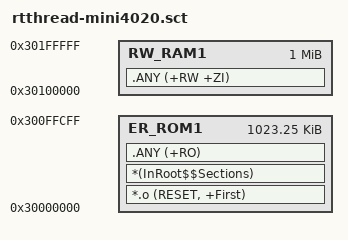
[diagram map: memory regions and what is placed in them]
; *************************************************************
; *** Scatter-Loading Description File generated by uVision ***
; *************************************************************

; *************************************************************
; *** Scatter-Loadig Description File generated by uVision ***n
; *************************************************************


LR_ROM1 0x30000000 0x0FFD00 ; load region size_region
  {
    ER_ROM1 0x30000000 0x0FFD00  ; load address = execution address
    {
        *.o (RESET, +First)
        *(InRoot$$Sections)
        .ANY (+RO)
    }
    RW_RAM1 0x30100000 0x100000 ; RW data
    {
        .ANY (+RW +ZI)
    }


}

